# STM32MP25_CM33 register map
File version: 1.3
CPU: CM33 r0p1, little endian, MPU, FPU, vendor SysTick, 8 interrupt priority bits
Registers are 32-bit, read-write, reset 0x0 unless marked. A register's access mark holds for its fields unless they carry their own. Offsets are from the block's base; [hi:lo] are bit positions; {n}, {i} and the like mark numbered series; 'fields as' and 'values as' point back to an identical list.

## ICACHE — ICACHE register block
Base 0x40470000
Same registers: ICACHE_S 0x50470000
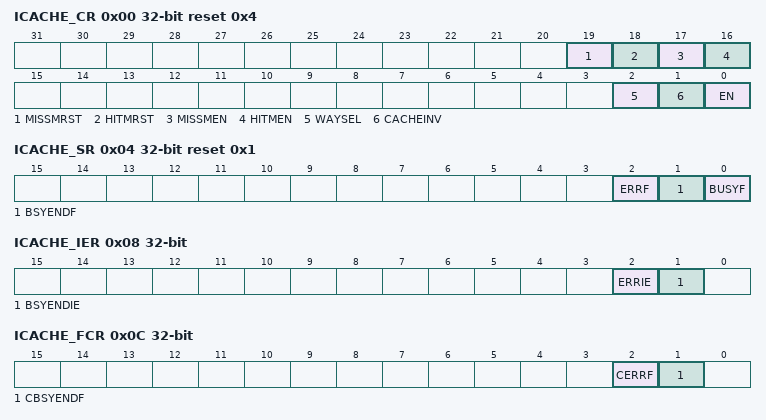
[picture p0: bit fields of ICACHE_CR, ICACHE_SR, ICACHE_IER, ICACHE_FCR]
0x00 ICACHE_CR reset 0x4 — ICACHE control register
  [19] MISSMRST — miss monitor reset
    0=release the cache miss monitor reset (needed to enable the counting); 1=reset cache miss monitor
  [18] HITMRST — hit monitor reset
    0=release the cache miss monitor reset (needed to enable the counting); 1=reset cache hit monitor
  [17] MISSMEN — miss monitor enable
    0=cache miss monitor switched off; 1=cache miss monitor enabled
  [16] HITMEN — hit monitor enable
    0=cache hit monitor switched off; 1=cache hit monitor enabled
  [2] WAYSEL — cache associativity mode selection
    0=direct mapped cache (1-way cache); 1=n-way set associative cache (reset value)
  [1] CACHEINV wo — cache invalidation
    0=no effect; 1=invalidate entire cache (all cache lines valid bit = 0)
  [0] EN — enable
    0=cache disabled; 1=cache enabled
0x04 ICACHE_SR ro reset 0x1 — ICACHE status register
  [2] ERRF — cache error flag
    0=no error; 1=an error occurred during the operation (cacheable write)
  [1] BSYENDF — busy end flag
    0=cache busy; 1=full invalidate CACHEINV operation finished
  [0] BUSYF — busy flag
    0=cache not busy on a CACHEINV operation; 1=cache executing a full invalidate CACHEINV operation
0x08 ICACHE_IER — ICACHE interrupt enable register
  [2] ERRIE — interrupt enable on cache error
    0=interrupt disabled on error; 1=interrupt enabled on error
  [1] BSYENDIE — interrupt enable on busy end
    0=interrupt disabled on busy end; 1=interrupt enabled on busy end
0x0C ICACHE_FCR wo — ICACHE flag clear register
  [2] CERRF — clear cache error flag
    0=no effect; 1=clears ERRF flag in ICACHE_SR
  [1] CBSYENDF — clear busy end flag
    0=no effect; 1=clears BSYENDF flag in ICACHE_SR
0x10 ICACHE_HMONR ro — ICACHE hit monitor register
  [31:0] HITMON — cache hit monitor counter
0x14 ICACHE_MMONR ro — ICACHE miss monitor register
  [15:0] MISSMON — cache miss monitor counter
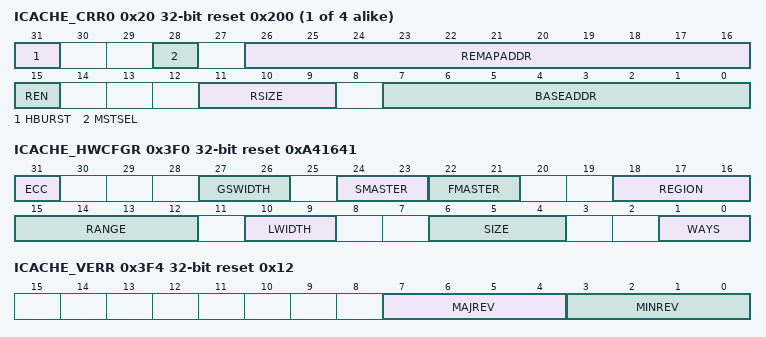
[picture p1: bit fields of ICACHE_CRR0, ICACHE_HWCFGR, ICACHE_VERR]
{0x20+4i} ICACHE_CRR{i} reset 0x200 (i=0..3) — ICACHE region {i} configuration register
  [31] HBURST — output burst type for region x
    0=WRAP; 1=INCR
  [28] MSTSEL — AHB cache master selection for region x
    0=no action (master1 selected by default); 1=master2 selected
  [26:16] REMAPADDR — remapped address for region x
  [15] REN — enable for region x
    0=disabled; 1=enabled
  [11:9] RSIZE — size for region x
    1=2 Mbytes; 2=4 Mbytes; 3=8 Mbytes; 4=16 Mbytes; 5=32 Mbytes; 6=64 Mbytes; 7=128 Mbytes
  [7:0] BASEADDR — base address for region x
0x3F0 ICACHE_HWCFGR ro reset 0xA41641 — ICACHE hardware configuration register
  [31] ECC — error detection and correction support
    0=no ECC hardware support; 1=ECC hardware support
  [27:26] GSWIDTH — data size of the AHB slave interface
    0=32-bit; 1=64-bit; 2=128-bit
  [24:23] SMASTER — data size of the second AHB master interface (master2)
    0=no second master (single master cache); 1=32-bit; 2=64-bit
  [22:21] FMASTER — data size of the first AHB master interface (master1)
    1=32-bit; 2=64-bit; 3=128-bit
  [18:16] REGION — number of regions that can be remapped
    0=no region; 1=1 region; 2=2 regions; 3=3 regions; 4=4 regions
  [15:12] RANGE — range granularity of remapped memory regions
    values as ICACHE_CRR0.RSIZE
  [10:9] LWIDTH — cache line width
    1=64-bit (8 bytes per line); 2=128-bit (16 bytes per line); 3=256-bit (32 bytes per line)
  [6:4] SIZE — cache size
    1=2-Kbyte; 2=4-Kbyte; 3=8-Kbyte; 4=16-Kbyte; 5=32-Kbyte
  [1:0] WAYS — cache associativity, number of ways
    1=2-way set associative; 2=4-way set associative
0x3F4 ICACHE_VERR ro reset 0x12 — ICACHE version register
  [7:4] MAJREV — ICACHE major revision
  [3:0] MINREV — ICACHE minor revision
0x3F8 ICACHE_IPIDR ro reset 0x100081 — ICACHE identification register
  [31:0] ID — ICACHE identification
0x3FC ICACHE_SIDR ro reset 0xA3C5DD01 — ICACHE size identification register
  [31:0] SID — ICACHE address space size identification
